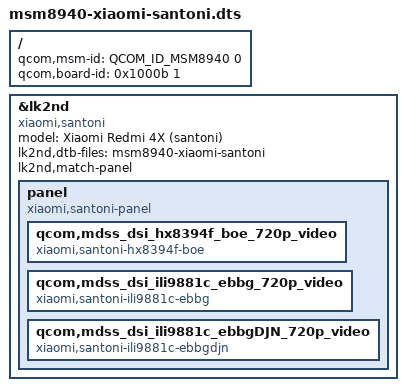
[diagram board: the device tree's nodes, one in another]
// SPDX-License-Identifier: BSD-3-Clause

#include <skeleton64.dtsi>
#include <lk2nd.dtsi>

/ {
	qcom,msm-id = <QCOM_ID_MSM8940 0>;
	qcom,board-id = <0x1000b 1>;
};

&lk2nd {
	model = "Xiaomi Redmi 4X (santoni)";
	compatible = "xiaomi,santoni";

	lk2nd,dtb-files = "msm8940-xiaomi-santoni";

	lk2nd,match-panel;
	panel {
		compatible = "xiaomi,santoni-panel", "lk2nd,panel";

		qcom,mdss_dsi_hx8394f_boe_720p_video {
			compatible = "xiaomi,santoni-hx8394f-boe";
		};
		qcom,mdss_dsi_ili9881c_ebbg_720p_video {
			compatible = "xiaomi,santoni-ili9881c-ebbg";
		};
		qcom,mdss_dsi_ili9881c_ebbgDJN_720p_video {
			compatible = "xiaomi,santoni-ili9881c-ebbgdjn";
		};
	};
};
